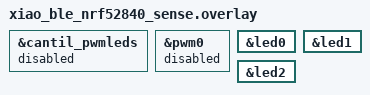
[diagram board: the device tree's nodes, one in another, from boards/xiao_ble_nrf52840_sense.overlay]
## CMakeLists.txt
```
# SPDX-License-Identifier: GPL-3.0-or-later
#
# Step-1 factory image — creates the LittleFS volume and writes its identity
# marker, then stops. No CA, no transport, no gesture, no key material.
#
# This is the only Cantil binary that contains lfs_format. Production is built
# with CONFIG_FILE_SYSTEM_MKFS=n and physically cannot format the volume; the
# ability to do so lives here, in an image flashed deliberately at a bench.
#
# Build:
#   scripts/build.sh --factory
#
# See docs/roadmap/two-step-provisioning.md.

cmake_minimum_required(VERSION 3.20.0)

# The shared board overlays live in firmware/boards and reference bindings
# under firmware/dts. Point DTS_ROOT at firmware/ so this app resolves them
# exactly as the production app does — the factory image and production MUST
# agree on the storage partition, since the marker's whole purpose is to
# assert that they do.
list(APPEND DTS_ROOT ${CMAKE_CURRENT_SOURCE_DIR}/..)

find_package(Zephyr REQUIRED HINTS $ENV{ZEPHYR_BASE})
project(cantil_factory VERSION 0.2.0)

target_sources(app PRIVATE
    src/main.c
    ${CMAKE_CURRENT_SOURCE_DIR}/../src/storage/volume_marker.c
    ${CMAKE_CURRENT_SOURCE_DIR}/../src/crypto/device_id.c
)

target_include_directories(app PRIVATE
    ${CMAKE_CURRENT_SOURCE_DIR}/../src
)
```

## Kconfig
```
# SPDX-License-Identifier: GPL-3.0-or-later

mainmenu "Cantil factory image"

# Mirror of firmware/Kconfig:CANTIL_STORAGE_EXTERNAL. Defined locally so this
# app builds standalone against Kconfig.zephyr without pulling in the full
# firmware Kconfig tree (USB/BLE/IMU/gesture/CA). storage_partition.h keys off
# CONFIG_CANTIL_STORAGE_EXTERNAL to choose between the cantil_storage node on
# external QSPI and the board's own storage_partition — keep the symbol name
# and semantics in sync with the production definition.
config CANTIL_STORAGE_EXTERNAL
	bool "LittleFS lives on the external QSPI part (cantil_storage node)"
	default n

config CANTIL_FACTORY_FORCE
	bool "Format a volume that already holds data"
	default n
	help
	  By default the factory image refuses to format anything except a
	  partition that will not mount — the only state that is good evidence
	  of a blank device.

	  In particular it refuses when the volume mounts but carries no marker.
	  That state is ambiguous: it is what a factory-fresh volume looks like,
	  and equally what a fully provisioned pre-marker device looks like.
	  Both units in development are in exactly that state. Formatting on
	  that evidence would destroy an unexportable CA key.

	  It also refuses when a valid marker is present (the device is already
	  initialised — reformatting would discard live keys) and when the
	  marker mismatches (wrong partition or another die's volume, where
	  formatting is the worst available response).

	  Set this to y only to deliberately re-initialise a device whose
	  contents you are willing to lose. It is not needed for a genuinely
	  new device.

source "Kconfig.zephyr"
```

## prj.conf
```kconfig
# Step-1 factory image.
#
# Deliberately minimal: flash, LittleFS, CRC, logging. No crypto stack, no
# transport, no gesture, no CA. This is the only image that carries
# lfs_format, so its surface area is kept as small as it can be.

CONFIG_FLASH=y
CONFIG_FLASH_MAP=y
CONFIG_FILE_SYSTEM=y
CONFIG_FILE_SYSTEM_LITTLEFS=y
CONFIG_FS_LITTLEFS_FMP_DEV=y

# The whole point of this image. Production sets this to n.
CONFIG_FILE_SYSTEM_MKFS=y

# crc32_ieee, for the volume identity marker's integrity field
CONFIG_CRC=y

CONFIG_LOG=y
CONFIG_LOG_DEFAULT_LEVEL=3

# RTT log backend — emits over SWD even with no USB console attached.
CONFIG_USE_SEGGER_RTT=y
CONFIG_LOG_BACKEND_RTT=y

CONFIG_MAIN_STACK_SIZE=4096
CONFIG_HEAP_MEM_POOL_SIZE=8192

# Status LED feedback via the generic LED API (led.h) on the board's gpio-leds
# — so a bench operator sees the result (green=done, red=refused/failed) without
# a console attached. The app overlay reverts the RGB pins from PWM to gpio-leds.
CONFIG_GPIO=y
CONFIG_LED=y
CONFIG_LED_GPIO=y
# Only the gpio-led backend; the PWM LED driver would try to bind the RGB pins'
# now-disabled pwm0 and fails to link.
CONFIG_LED_PWM=n

CONFIG_REBOOT=y
```

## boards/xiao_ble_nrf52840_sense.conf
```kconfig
# Seeed Studio XIAO BLE Sense — factory image.
#
# Only what is needed to reach the QSPI part and report what happened. The
# production board .conf additionally brings up USB, PWM/LED, GPIO tap input,
# I2C and the CA stack; none of that is wanted here.

# LittleFS lives on the external QSPI part (cantil_storage node in the
# shared overlay), not on internal flash.
CONFIG_CANTIL_STORAGE_EXTERNAL=y

# External QSPI flash — hardware configured by board DTS; enable drivers
# explicitly, matching the production board .conf.
CONFIG_FLASH=y
CONFIG_NORDIC_QSPI_NOR=y
CONFIG_NORDIC_QSPI_NOR_FLASH_LAYOUT_PAGE_SIZE=4096
CONFIG_MPU_ALLOW_FLASH_WRITE=y

# USB CDC/ACM console, so the bench operator can read the result over the
# same cable used to flash. The shared overlay points zephyr,console at
# cdc_acm_uart1 (the second CDC port).
#
# Exactly the two symbols the production board .conf sets, and no more.
# Adding CONFIG_USB_DEVICE_STACK on top pulls in the device_next stack
# alongside the legacy one and both compile a CDC ACM class for the same
# devicetree nodes, which fails at link with duplicate __device_dts_ord_*.
# USB_DEVICE_INITIALIZE_AT_BOOT, set by the board dtsi, handles enumeration.
CONFIG_USB_CDC_ACM=y
CONFIG_UART_LINE_CTRL=y
```

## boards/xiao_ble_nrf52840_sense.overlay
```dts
/*
 * SPDX-License-Identifier: GPL-3.0-or-later
 *
 * Factory image, XIAO BLE Sense.
 *
 * Includes the production overlay verbatim rather than restating the storage
 * partition. That is not laziness — it is the point. The volume identity
 * marker records the offset and size the volume was created for, and
 * production refuses to mount a volume whose marker disagrees. If this file
 * carried its own copy of the cantil_storage node, the two could drift, and
 * every device made in between would be born with a marker that its own
 * production firmware rejects.
 *
 * One source of truth, included from both sides.
 */
#include "../../boards/xiao_ble_nrf52840_sense.overlay"

/*
 * Status-LED feedback. The shared overlay repurposes the RGB pins (P0.26/30/06)
 * to PWM and disables the board's gpio-leds; the factory image runs no PWM, so
 * revert to the plain gpio-leds and let the generic LED API drive them.
 * led0 = Red, led1 = Green, led2 = Blue (all GPIO_ACTIVE_LOW).
 */
&cantil_pwmleds { status = "disabled"; };
&pwm0 { status = "disabled"; };
&led0 { status = "okay"; };
&led1 { status = "okay"; };
&led2 { status = "okay"; };
```

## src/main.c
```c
/* SPDX-License-Identifier: GPL-3.0-or-later */
/* See LICENSE at the repo root. */

/*
 * Step-1 factory image.
 *
 * Creates the LittleFS volume on the Cantil storage partition, writes its
 * identity marker, and stops. It generates no keys and holds no secrets.
 *
 * Why this is a separate binary at all: production is built with
 * CONFIG_FILE_SYSTEM_MKFS=n, so lfs_format is not linked into it and no bug,
 * error path, or compromised command handler can format the volume that holds
 * an unexportable CA key. The ability to format has to live somewhere, so it
 * lives here — in an image an operator flashes deliberately, once, at a bench.
 *
 * ── The refusal policy ────────────────────────────────────────────────────
 *
 * Three defects in this codebase have now had the same shape: an ambiguous
 * signal treated as licence to destroy data. A partition that failed to mount
 * was read as "corrupt, reformat". An empty key slot was read as "new device,
 * provision". A second mount returning -EBUSY was read as "broken filesystem".
 * Each was a guess, and each guess destroyed keys that cannot be recovered.
 *
 * This image formats flash for a living, so it gets the strictest version of
 * the rule. It proceeds on exactly one state:
 *
 *   mount FAILS          → nothing readable is there. Format, write marker.
 *
 * and refuses on every other, because each is either evidence of live data or
 * ambiguous between live data and blankness:
 *
 *   mount OK, VALID      → already initialised. Formatting discards live keys.
 *   mount OK, UNMARKED   → AMBIGUOUS. This is what a fresh volume looks like
 *                          and equally what a fully provisioned pre-marker
 *                          device looks like. Nothing on the volume separates
 *                          them, so this image must not guess.
 *   mount OK, MISMATCH   → wrong partition, or another die's volume. Whatever
 *                          is really there, formatting is the worst response.
 *
 * CONFIG_CANTIL_FACTORY_FORCE overrides the refusals for an operator who has
 * decided the contents are expendable. It is not needed for a new device.
 */

#include <zephyr/kernel.h>
#include <zephyr/fs/fs.h>
#include <zephyr/fs/littlefs.h>
#include <zephyr/logging/log.h>
#include <zephyr/sys/reboot.h>
#include <zephyr/drivers/led.h>
#include <errno.h>

#include "storage/volume_marker.h"
#include "storage/storage_partition.h"
#include "crypto/device_id.h"

LOG_MODULE_REGISTER(factory, LOG_LEVEL_INF);

FS_LITTLEFS_DECLARE_DEFAULT_CONFIG(lfs_data);

/* Status LED — the board's gpio-leds, re-enabled in the app overlay. Indices
 * follow child order: 0 = Red, 1 = Green, 2 = Blue (all active-low). */
#define LED_RED   0
#define LED_GREEN 1
#define LED_BLUE  2
static const struct device *const leds = DEVICE_DT_GET(DT_PARENT(DT_NODELABEL(led0)));

static void led_only(int which)
{
	if (!device_is_ready(leds)) {
		return;
	}
	led_off(leds, LED_RED);
	led_off(leds, LED_GREEN);
	led_off(leds, LED_BLUE);
	if (which >= 0) {
		led_on(leds, which);
	}
}

/*
 * The image's final, human-readable verdict — blink one channel forever so an
 * operator with no console still learns the outcome:
 *   green, slow heartbeat → volume created and marker verified (done)
 *   red, fast             → refused or failed (nothing written / not usable)
 */
static FUNC_NORETURN void park_blink(int which, int on_ms, int off_ms)
{
	led_only(-1);
	while (1) {
		if (device_is_ready(leds)) {
			led_on(leds, which);
		}
		k_sleep(K_MSEC(on_ms));
		if (device_is_ready(leds)) {
			led_off(leds, which);
		}
		k_sleep(K_MSEC(off_ms));
	}
}

#define park_ok()     park_blink(LED_GREEN, 150, 850)
#define park_failed() park_blink(LED_RED, 150, 250)

/*
 * FS_MOUNT_FLAG_NO_FORMAT is not optional here. Zephyr's littlefs backend
 * formats from inside fs_mount() when the mount fails and this flag is clear —
 * which would erase the volume before this image had decided whether it was
 * allowed to. The whole policy above depends on a mount attempt being a
 * read-only probe, and only this flag makes it one.
 */
static struct fs_mount_t factory_mount = {
	.type = FS_LITTLEFS,
	.mnt_point = MOUNT_POINT,
	.fs_data = &lfs_data,
	.storage_dev = (void *)LFS_PARTITION,
	.flags = FS_MOUNT_FLAG_NO_FORMAT,
};

static void banner(void)
{
	uint8_t id[8];

	crypto_device_id(id);

	LOG_INF("Cantil factory image (step 1 of 2)");
	LOG_INF("device  %02x%02x%02x%02x%02x%02x%02x%02x", id[0], id[1], id[2], id[3], id[4],
		id[5], id[6], id[7]);
	LOG_INF("target  offset 0x%08x  size 0x%08x", (unsigned int)LFS_PARTITION_OFF,
		(unsigned int)LFS_PARTITION_SIZE);
}

/* Log the refusal in a form the operator can act on, then park. */
static void refuse(const char *what, const char *why)
{
	LOG_ERR("refusing to format: %s", what);
	LOG_ERR("%s", why);
	if (!IS_ENABLED(CONFIG_CANTIL_FACTORY_FORCE)) {
		LOG_ERR("if the contents really are expendable, rebuild with");
		LOG_ERR("CONFIG_CANTIL_FACTORY_FORCE=y and flash again");
	}
}

/* Create the volume and its marker. The only path that writes to flash. */
static int initialise(void)
{
	int ret;

	LOG_WRN("formatting %s (offset 0x%08x, size 0x%08x)", MOUNT_POINT,
		(unsigned int)LFS_PARTITION_OFF, (unsigned int)LFS_PARTITION_SIZE);

	ret = fs_mkfs(FS_LITTLEFS, (uintptr_t)LFS_PARTITION, NULL, 0);
	if (ret) {
		LOG_ERR("fs_mkfs failed: %d", ret);
		return ret;
	}

	ret = fs_mount(&factory_mount);
	if (ret) {
		LOG_ERR("mount after format failed: %d", ret);
		return ret;
	}

	ret = storage_volume_marker_write();
	if (ret) {
		LOG_ERR("marker write failed: %d", ret);
		return ret;
	}

	/*
	 * Verify by reading back rather than trusting the write. A volume that
	 * leaves the bench with a marker production will reject is worse than
	 * one with no marker at all — the latter can still be adopted.
	 */
	if (storage_volume_verify() != STORAGE_VOLUME_VALID) {
		LOG_ERR("marker did not verify after writing — not usable");
		return -EIO;
	}

	return 0;
}

int main(void)
{
	/* The USB console enumerates a moment after boot; without this the
	 * entire report is emitted into a port nobody is attached to yet.
	 * RTT sees it either way. */
	k_sleep(K_SECONDS(3));

	led_only(LED_BLUE); /* blue = image running / working */
	banner();

	int ret = fs_mount(&factory_mount);
	bool may_format = false;

	if (ret == -ENODEV) {
		LOG_ERR("storage device not found — check the board's QSPI "
			"configuration; nothing was written");
		park_failed();
	}

	if (ret) {
		/*
		 * The one unambiguous state. Note this is still not proof of a
		 * blank part — a misdeclared partition also fails to mount —
		 * which is why the offset and size go into the log above and
		 * into the marker below.
		 */
		LOG_INF("volume does not mount (%d) — treating as uninitialised", ret);
		may_format = true;
	} else {
		switch (storage_volume_verify()) {
		case STORAGE_VOLUME_VALID:
			LOG_INF("volume is already initialised and its marker "
				"verifies");
			refuse("this device is already provisioned",
			       "reformatting would discard live key material");
			break;
		case STORAGE_VOLUME_UNMARKED:
			refuse("volume mounts but carries no identity marker",
			       "that is ambiguous — it is what a fresh volume "
			       "looks like AND what a provisioned pre-marker "
			       "device looks like; nothing here can tell them "
			       "apart");
			LOG_ERR("to adopt an existing known-good volume instead,");
			LOG_ERR("flash production with CONFIG_CANTIL_VOLUME_MARKER_ADOPT=y");
			break;
		case STORAGE_VOLUME_MISMATCH:
			refuse("volume marker does not match this build",
			       "wrong partition, or a volume belonging to "
			       "another device (detail logged above)");
			break;
		}
	}

	if (!may_format && IS_ENABLED(CONFIG_CANTIL_FACTORY_FORCE)) {
		LOG_WRN("CANTIL_FACTORY_FORCE is set — overriding the refusal");
		LOG_WRN("existing contents, including any CA key, will be lost");
		if (ret == 0) {
			(void)fs_unmount(&factory_mount);
		}
		may_format = true;
	}

	if (!may_format) {
		LOG_ERR("nothing was written");
		park_failed();
	}

	if (initialise()) {
		LOG_ERR("initialisation FAILED — do not ship this device");
		park_failed();
	}

	LOG_INF("volume initialised and marker verified");
	LOG_INF("step 1 complete — flash the Cantil firmware to continue");
	park_ok();
}
```
